AUTOSAR XML (schema 4-2-1)
package /RootP_ASWC_SATELLITE_CORE1_MonitoringASILB
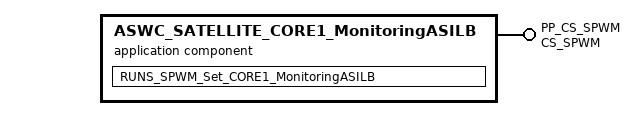
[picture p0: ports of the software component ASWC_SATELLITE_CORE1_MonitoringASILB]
  application sw component type ASWC_SATELLITE_CORE1_MonitoringASILB
    provide port PP_CS_SPWM: server-com-spec{operation=Set, queue-length=1}, provided-interface=CS_SPWM
    behavior IB_ASWC_SATELLITE_CORE1_MonitoringASILB: handle-termination-and-restart=NO-SUPPORT
      operation invoked event CS_SPWM_Set_OIE_CORE1_MonitoringASILB: start-on-event=RUNS_SPWM_Set_CORE1_MonitoringASILB, operation=PP_CS_SPWM.Set
      runnable RUNS_SPWM_Set_CORE1_MonitoringASILB: can-be-invoked-concurrently=true
  swc implementation ASWC_SATELLITE_CORE1_MonitoringASILB_Impl: programming-language=C, sw-version=1.0.0, vendor-id=0, behavior=IB_ASWC_SATELLITE_CORE1_MonitoringASILB
    code-descriptors:
      code SRC: artifact-descriptors=autosar-engineering-object={short-label=EngObject, category=SWSRC}
    resource consumption Resources
      memory section CODE: sw-addrmethod=CODE_ASWC_SATELLITE_CORE1_MonitoringASILB
  sw addr method CODE_ASWC_SATELLITE_CORE1_MonitoringASILB: memory-allocation-keyword-policy=ADDR-METHOD-SHORT-NAME-AND-ALIGNMENT, section-type=CODE
